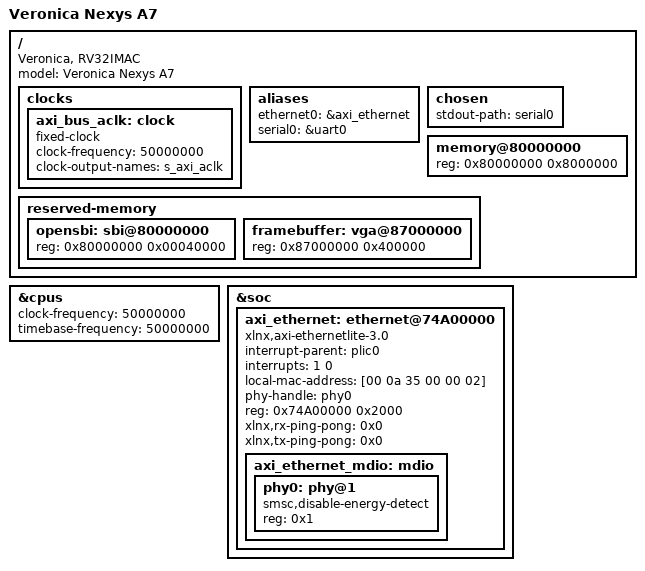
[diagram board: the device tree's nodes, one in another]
// SPDX-License-Identifier: (GPL-2.0 OR MIT)

#include "veronica_basedev.dtsi"
#include <dt-bindings/gpio/gpio.h>

/ {
	model = "Veronica Nexys A7";
	compatible = "Veronica, RV32IMAC";
	
  clocks {
		axi_bus_aclk: clock {
      #clock-cells = <0>;
			compatible = "fixed-clock";
			clock-frequency = <50000000>;
			clock-output-names = "s_axi_aclk";
		};
	};
	
  aliases {
		ethernet0 = &axi_ethernet;
		serial0 = &uart0;
	};

	chosen {
		stdout-path = "serial0";
	};

	memory@80000000 {
    status = "okay";
		device_type = "memory";
		reg = <0x80000000 0x8000000>;
	};
	
	reserved-memory {
		#address-cells = <1>;
		#size-cells = <1>;
		ranges;

		opensbi: sbi@80000000 {
			reg = <0x80000000 0x00040000>;
		};
		
		framebuffer: vga@87000000 {
			reg = <0x87000000 0x400000>;
		};
	};
};

&cpus {
  clock-frequency = <50000000>;
  timebase-frequency = <50000000>;
};

&soc {
	axi_ethernet: ethernet@74A00000 {
		compatible = "xlnx,axi-ethernetlite-3.0", "xlnx,xps-ethernetlite-1.00.a";
		device_type = "network";
		interrupt-parent = <&plic0>;
		interrupts = <1 0>;
		local-mac-address = [00 0a 35 00 00 02];
		phy-handle = <&phy0>;
		reg = <0x74A00000 0x2000>;
		xlnx,rx-ping-pong = <0x0>;
		xlnx,tx-ping-pong = <0x0>;
		axi_ethernet_mdio: mdio {
			#address-cells = <1>;
			#size-cells = <0>;
			phy0: phy@1 {
				device_type = "ethernet-phy";
				smsc,disable-energy-detect;
				reg = <0x1>;
			};
		};
	};
	
	//axi_vga_fb: axi_vga_fb@74A10000 {
	//	compatible = "xlkn,xps-tft-2.00.a";
	//	interrupt-parent = <&plic0>;
	//	interrupts = <2>;
	//	reg = <0x74A10000 0x10000>;
	//	xlnx,dcr-splb-slave-if = <0x1>;
	//};
};
